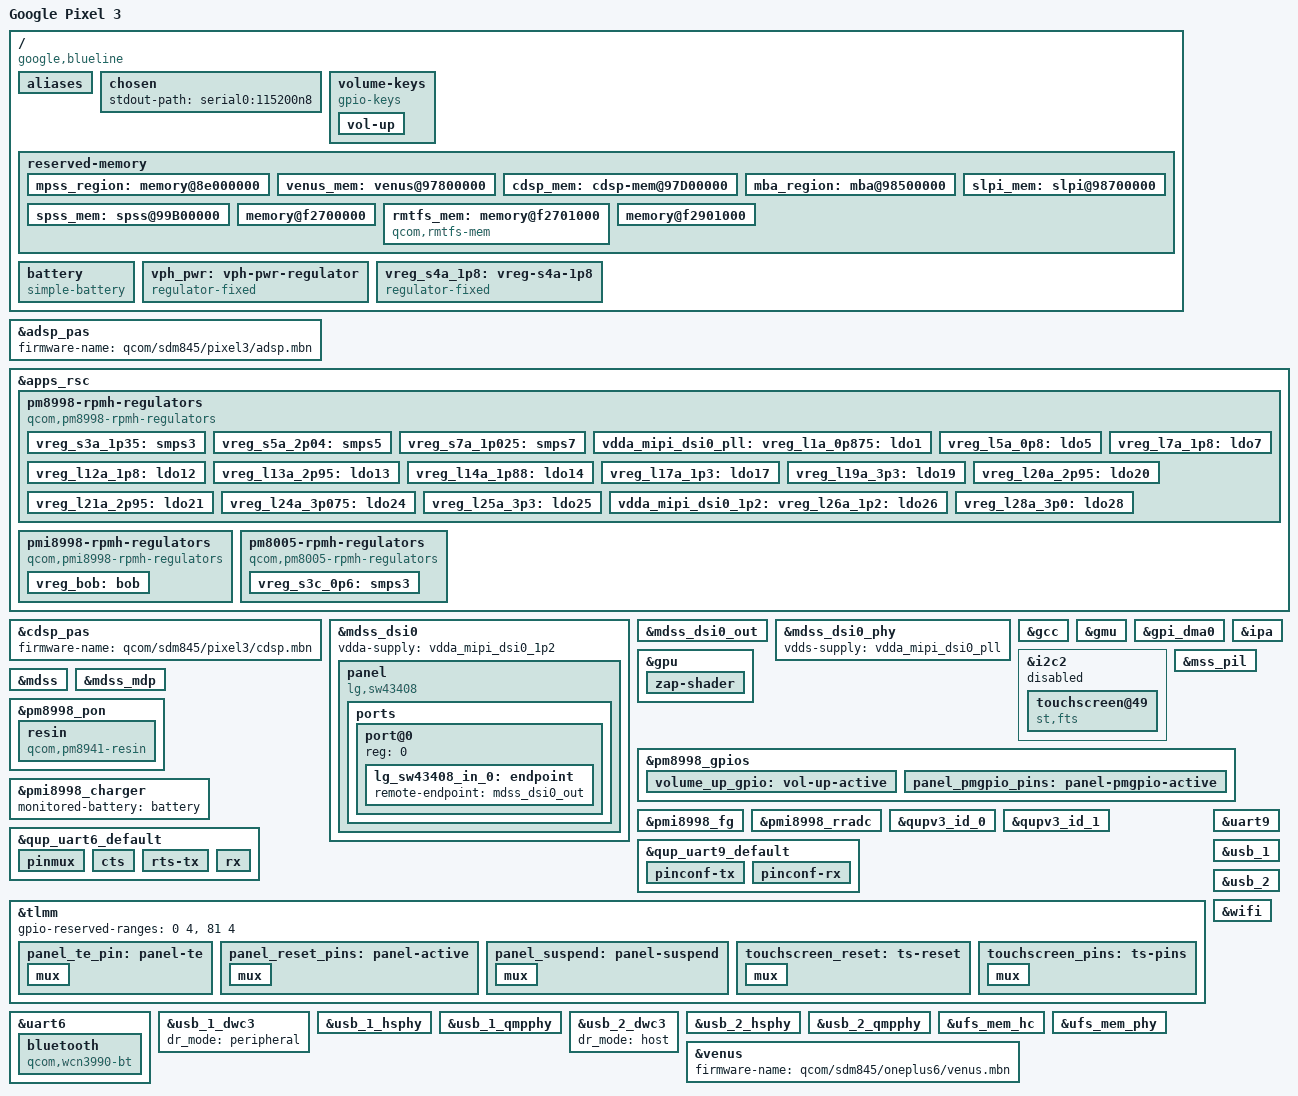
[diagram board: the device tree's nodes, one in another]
// SPDX-License-Identifier: GPL-2.0

/dts-v1/;

#include <dt-bindings/dma/qcom-gpi.h>
#include <dt-bindings/input/linux-event-codes.h>
#include <dt-bindings/interrupt-controller/irq.h>
#include <dt-bindings/regulator/qcom,rpmh-regulator.h>

#include "sdm845.dtsi"
#include "pm8998.dtsi"
#include "pmi8998.dtsi"

/delete-node/ &mpss_region;
/delete-node/ &venus_mem;
/delete-node/ &cdsp_mem;
/delete-node/ &mba_region;
/delete-node/ &slpi_mem;
/delete-node/ &spss_mem;
/delete-node/ &rmtfs_mem;

/ {
	model = "Google Pixel 3";
	compatible = "google,blueline", "qcom,sdm845";
	qcom,board-id = <0x00021505 0>;
	qcom,msm-id = <321 0x20001>;

	aliases {
		serial0 = &uart9;
		serial1 = &uart6;
	};

	chosen {
		stdout-path = "serial0:115200n8";
	};

	volume-keys {
		compatible = "gpio-keys";
		label = "Volume keys";
		autorepeat;

		pinctrl-names = "default";
		pinctrl-0 = <&volume_up_gpio>;

		vol-up {
			label = "Volume Up";
			linux,code = <KEY_VOLUMEUP>;
			gpios = <&pm8998_gpios 6 GPIO_ACTIVE_LOW>;
			debounce-interval = <15>;
		};
	};

	reserved-memory {
		#address-cells = <2>;
		#size-cells = <2>;
		ranges;

		mpss_region: memory@8e000000 {
			reg = <0 0x8e000000 0 0x9800000>;
			no-map;
		};

		venus_mem: venus@97800000 {
			reg = <0 0x97800000 0 0x500000>;
			no-map;
		};

		cdsp_mem: cdsp-mem@97D00000 {
			reg = <0 0x97D00000 0 0x800000>;
			no-map;
		};

		mba_region: mba@98500000 {
			reg = <0 0x98500000 0 0x200000>;
			no-map;
		};

		slpi_mem: slpi@98700000 {
			reg = <0 0x98700000 0 0x1400000>;
			no-map;
		};

		spss_mem: spss@99B00000 {
			reg = <0 0x99B00000 0 0x100000>;
			no-map;
		};

		/* rmtfs lower guard */
		memory@f2700000 {
			reg = <0 0xf2700000 0 0x1000>;
			no-map;
		};

		rmtfs_mem: memory@f2701000 {
			compatible = "qcom,rmtfs-mem";
			reg = <0 0xf2701000 0 0x200000>;
			no-map;

			qcom,client-id = <1>;
			qcom,vmid = <15>;
		};

		/* rmtfs upper guard */
		memory@f2901000 {
			reg = <0 0xf2901000 0 0x1000>;
			no-map;
		};
	};

	battery: battery {
		compatible = "simple-battery";

		charge-full-design-microamp-hours = <2970000>;
		voltage-min-design-microvolt = <3600000>;
		voltage-max-design-microvolt = <4400000>;
	};


	vph_pwr: vph-pwr-regulator {
		compatible = "regulator-fixed";
		regulator-name = "vph_pwr";
		regulator-min-microvolt = <3700000>;
		regulator-max-microvolt = <3700000>;
	};

	vreg_s4a_1p8: vreg-s4a-1p8 {
		compatible = "regulator-fixed";
		regulator-name = "vreg_s4a_1p8";

		regulator-min-microvolt = <1800000>;
		regulator-max-microvolt = <1800000>;
		regulator-always-on;
		regulator-boot-on;

		vin-supply = <&vph_pwr>;
	};
};

&adsp_pas {
	status = "okay";

	firmware-name = "qcom/sdm845/pixel3/adsp.mbn";
};

&apps_rsc {
	pm8998-rpmh-regulators {
		compatible = "qcom,pm8998-rpmh-regulators";
		qcom,pmic-id = "a";
		vdd-s1-supply = <&vph_pwr>;
		vdd-s2-supply = <&vph_pwr>;
		vdd-s3-supply = <&vph_pwr>;
		vdd-s4-supply = <&vph_pwr>;
		vdd-s5-supply = <&vph_pwr>;
		vdd-s6-supply = <&vph_pwr>;
		vdd-s7-supply = <&vph_pwr>;
		vdd-s8-supply = <&vph_pwr>;
		vdd-s9-supply = <&vph_pwr>;
		vdd-s10-supply = <&vph_pwr>;
		vdd-s11-supply = <&vph_pwr>;
		vdd-s12-supply = <&vph_pwr>;
		vdd-s13-supply = <&vph_pwr>;
		vdd-l1-l27-supply = <&vreg_s7a_1p025>;
		vdd-l2-l8-l17-supply = <&vreg_s3a_1p35>;
		vdd-l3-l11-supply = <&vreg_s7a_1p025>;
		vdd-l4-l5-supply = <&vreg_s7a_1p025>;
		vdd-l6-supply = <&vph_pwr>;
		vdd-l7-l12-l14-l15-supply = <&vreg_s5a_2p04>;
		vdd-l9-supply = <&vreg_bob>;
		vdd-l10-l23-l25-supply = <&vreg_bob>;
		vdd-l13-l19-l21-supply = <&vreg_bob>;
		vdd-l16-l28-supply = <&vreg_bob>;
		vdd-l18-l22-supply = <&vreg_bob>;
		vdd-l20-l24-supply = <&vreg_bob>;
		vdd-l26-supply = <&vreg_s3a_1p35>;
		vin-lvs-1-2-supply = <&vreg_s4a_1p8>;

		vreg_s3a_1p35: smps3 {
			regulator-min-microvolt = <1352000>;
			regulator-max-microvolt = <1352000>;
		};

		vreg_s5a_2p04: smps5 {
			regulator-min-microvolt = <1904000>;
			regulator-max-microvolt = <2040000>;
		};

		vreg_s7a_1p025: smps7 {
			regulator-min-microvolt = <900000>;
			regulator-max-microvolt = <1028000>;
		};

		vdda_mipi_dsi0_pll:
		vreg_l1a_0p875: ldo1 {
			regulator-min-microvolt = <880000>;
			regulator-max-microvolt = <880000>;
			regulator-initial-mode = <RPMH_REGULATOR_MODE_HPM>;
			regulator-boot-on;
		};

		vreg_l5a_0p8: ldo5 {
			regulator-min-microvolt = <800000>;
			regulator-max-microvolt = <800000>;
			regulator-initial-mode = <RPMH_REGULATOR_MODE_HPM>;
		};

		vreg_l12a_1p8: ldo12 {
			regulator-min-microvolt = <1800000>;
			regulator-max-microvolt = <1800000>;
			regulator-initial-mode = <RPMH_REGULATOR_MODE_HPM>;
		};

		vreg_l7a_1p8: ldo7 {
			regulator-min-microvolt = <1800000>;
			regulator-max-microvolt = <1800000>;
			regulator-initial-mode = <RPMH_REGULATOR_MODE_HPM>;
		};

		vreg_l13a_2p95: ldo13 {
			regulator-min-microvolt = <1800000>;
			regulator-max-microvolt = <2960000>;
			regulator-initial-mode = <RPMH_REGULATOR_MODE_HPM>;
		};

		vreg_l14a_1p88: ldo14 {
			regulator-min-microvolt = <1800000>;
			regulator-max-microvolt = <1800000>;
			regulator-initial-mode = <RPMH_REGULATOR_MODE_HPM>;
			regulator-boot-on;
			/*
			 * We can't properly bring the panel back if it gets turned off
			 * so keep it's regulators always on for now.
			 */
			regulator-always-on;
		};

		vreg_l17a_1p3: ldo17 {
			regulator-min-microvolt = <1304000>;
			regulator-max-microvolt = <1304000>;
			regulator-initial-mode = <RPMH_REGULATOR_MODE_HPM>;
		};

		vreg_l19a_3p3: ldo19 {
			regulator-min-microvolt = <3300000>;
			regulator-max-microvolt = <3312000>;
			qcom,init-voltage = <3300000>;
			qcom,initial-mode = <RPMH_REGULATOR_MODE_HPM>;
			/*
			 * The touchscreen needs this to be 3.3v, which is apparently
			 * quite close to the hardware limit for this LDO (3.312v)
			 * It must be kept in high power mode to prevent TS brownouts
			 */
			regulator-allowed-modes = <RPMH_REGULATOR_MODE_HPM>;
		};

		vreg_l20a_2p95: ldo20 {
			regulator-min-microvolt = <2960000>;
			regulator-max-microvolt = <2968000>;
			regulator-initial-mode = <RPMH_REGULATOR_MODE_HPM>;
		};

		vreg_l21a_2p95: ldo21 {
			regulator-min-microvolt = <2960000>;
			regulator-max-microvolt = <2968000>;
			regulator-initial-mode = <RPMH_REGULATOR_MODE_HPM>;
		};

		vreg_l24a_3p075: ldo24 {
			regulator-min-microvolt = <3088000>;
			regulator-max-microvolt = <3088000>;
			regulator-initial-mode = <RPMH_REGULATOR_MODE_HPM>;
		};

		vreg_l25a_3p3: ldo25 {
			regulator-min-microvolt = <3300000>;
			regulator-max-microvolt = <3312000>;
			regulator-initial-mode = <RPMH_REGULATOR_MODE_HPM>;
		};

		vdda_mipi_dsi0_1p2:
		vreg_l26a_1p2: ldo26 {
			regulator-min-microvolt = <1200000>;
			regulator-max-microvolt = <1200000>;
			regulator-initial-mode = <RPMH_REGULATOR_MODE_HPM>;
			regulator-boot-on;
		};

		vreg_l28a_3p0: ldo28 {
			regulator-min-microvolt = <2856000>;
			regulator-max-microvolt = <3008000>;
			regulator-initial-mode = <RPMH_REGULATOR_MODE_HPM>;
			regulator-boot-on;
			/*
			 * We can't properly bring the panel back if it gets turned off
			 * so keep it's regulators always on for now.
			 */
			regulator-always-on;
		};
	};

	pmi8998-rpmh-regulators {
		compatible = "qcom,pmi8998-rpmh-regulators";
		qcom,pmic-id = "b";

		vdd-bob-supply = <&vph_pwr>;

		vreg_bob: bob {
			regulator-min-microvolt = <3312000>;
			regulator-max-microvolt = <3600000>;
			regulator-initial-mode = <RPMH_REGULATOR_MODE_AUTO>;
			regulator-allow-bypass;
		};
	};

	pm8005-rpmh-regulators {
		compatible = "qcom,pm8005-rpmh-regulators";
		qcom,pmic-id = "c";

		vdd-s1-supply = <&vph_pwr>;
		vdd-s2-supply = <&vph_pwr>;
		vdd-s3-supply = <&vph_pwr>;
		vdd-s4-supply = <&vph_pwr>;

		vreg_s3c_0p6: smps3 {
			regulator-min-microvolt = <600000>;
			regulator-max-microvolt = <600000>;
		};
	};
};

&cdsp_pas {
	status = "okay";
	firmware-name = "qcom/sdm845/pixel3/cdsp.mbn";
};

&mdss_dsi0 {
	status = "okay";
	vdda-supply = <&vdda_mipi_dsi0_1p2>;

	panel {
		compatible = "lg,sw43408";
		reg = <0>;

		vddi-supply = <&vreg_l14a_1p88>;
		vpnl-supply = <&vreg_l28a_3p0>;

		reset-gpios = <&tlmm 6 GPIO_ACTIVE_LOW>;

		pinctrl-names = "default";
		pinctrl-0 = <&panel_reset_pins &panel_te_pin &panel_pmgpio_pins>;

		ports {
			#address-cells = <1>;
			#size-cells = <0>;

			port@0 {
				reg = <0>;
				lg_sw43408_in_0: endpoint {
					remote-endpoint = <&mdss_dsi0_out>;
				};
			};
		};
	};
};

&mdss_dsi0_out {
	remote-endpoint = <&lg_sw43408_in_0>;
	data-lanes = <0 1 2 3>;
};

&mdss_dsi0_phy {
	status = "okay";
	vdds-supply = <&vdda_mipi_dsi0_pll>;
};

&gcc {
	protected-clocks = <GCC_QSPI_CORE_CLK>,
			   <GCC_QSPI_CORE_CLK_SRC>,
			   <GCC_QSPI_CNOC_PERIPH_AHB_CLK>;
};

&gmu {
	status = "okay";
};

&gpi_dma0 {
	status = "okay";
};

&gpu {
	status = "okay";

	zap-shader {
		memory-region = <&gpu_mem>;
		firmware-name = "qcom/sdm845/pixel3/a630_zap.mbn";
	};
};

&i2c2 {
	status = "disabled";
	#dma-cells = <3>;

	dmas =  <&gpi_dma0 0 2 QCOM_GPI_I2C>,
		<&gpi_dma0 1 2 QCOM_GPI_I2C>;
	dma-names = "tx", "rx";

	touchscreen@49 {
		compatible = "st,fts";
		reg = <0x49>;
		pinctrl-names = "default";
		pinctrl-0 = <&touchscreen_pins &touchscreen_reset>;
		interrupt-parent = <&tlmm>;
		interrupts = <125 IRQ_TYPE_LEVEL_LOW>;
		avdd-supply = <&vreg_l14a_1p88>;
		vdd-supply = <&vreg_l19a_3p3>;
		// touchscreen-size-x = <1080>;
		// touchscreen-size-y = <2160>;

		st,irq-gpio = <&tlmm 125 0>;
		st,reset-gpio = <&tlmm 99 0>;
		st,switch_gpio = <&tlmm 136 0>;
		st,max-coords = <1079 2159>;
		st,regulator_dvdd = "vdd";
		st,regulator_avdd = "avdd";
	};
};

&ipa {
	status = "okay";

	memory-region = <&ipa_fw_mem>;
	firmware-name = "qcom/sdm845/pixel3/ipa_fws.mbn";
};

&mss_pil {
	status = "okay";
	firmware-name = "qcom/sdm845/pixel3/mba.mbn", "qcom/sdm845/pixel3/modem.mbn";
};

&mdss {
	status = "okay";
};

&mdss_mdp {
	status = "okay";
};

&pm8998_gpios {
	volume_up_gpio: vol-up-active {
		pins = "gpio6";
		function = "normal";
		input-enable;
		bias-pull-up;
		qcom,drive-strength = <0>;
	};

	panel_pmgpio_pins: panel-pmgpio-active {
		pins = "gpio2", "gpio5";
		function = "normal";
		input-enable;
		bias-disable;
		power-source = <0>;
	};
};

&pm8998_pon {
	resin {
		compatible = "qcom,pm8941-resin";
		interrupts = <0x0 0x8 1 IRQ_TYPE_EDGE_BOTH>;
		debounce = <15625>;
		bias-pull-up;
		linux,code = <KEY_VOLUMEDOWN>;
	};
};

&pmi8998_charger {
	status = "okay";
	monitored-battery = <&battery>;
};

&pmi8998_fg {
	status = "okay";
	monitored-battery = <&battery>;
	power-supplies = <&pmi8998_charger>;
};

&pmi8998_rradc {
	status = "okay";
};

&qupv3_id_0 {
	status = "okay";
};

&qupv3_id_1 {
	status = "okay";
};

&qup_uart6_default {
	pinmux {
		pins = "gpio45", "gpio46", "gpio47", "gpio48";
		function = "qup6";
	};

	cts {
		pins = "gpio45";
		bias-disable;
	};

	rts-tx {
		pins = "gpio46", "gpio47";
		drive-strength = <2>;
		bias-disable;
	};

	rx {
		pins = "gpio48";
		bias-pull-up;
	};
};

&qup_uart9_default {
	pinconf-tx {
		pins = "gpio4";
		drive-strength = <2>;
		bias-disable;
	};

	pinconf-rx {
		pins = "gpio5";
		drive-strength = <2>;
		bias-pull-up;
	};
};

&tlmm {
	gpio-reserved-ranges = <0 4>, <81 4>;

	panel_te_pin: panel-te {
		mux {
			pins = "gpio12";
			function = "mdp_vsync";
			drive-strength = <2>;
			bias-disable;
			input-enable;
		};
	};

	panel_reset_pins: panel-active {
		mux {
			pins = "gpio6", "gpio52";
			function = "gpio";
			drive-strength = <8>;
			bias-disable = <0>;
		};
	};

	panel_suspend: panel-suspend {
		mux {
			pins = "gpio6", "gpio52";
			function = "gpio";
			drive-strength = <2>;
			bias-pull-down;
		};
	};

	touchscreen_reset: ts-reset {
		mux {
			pins = "gpio99";
			function = "gpio";
			drive-strength = <8>;
			bias-pull-up;
			//output-high;
		};
	};

	touchscreen_pins: ts-pins {
		mux {
			pins = "gpio125";
			function = "gpio";
			drive-strength = <2>;
			bias-disable;
		};
	};
};

&uart6 {
	status = "okay";

	bluetooth {
		compatible = "qcom,wcn3990-bt";

		vddio-supply = <&vreg_s4a_1p8>;
		vddxo-supply = <&vreg_l7a_1p8>;
		vddrf-supply = <&vreg_l17a_1p3>;
		vddch0-supply = <&vreg_l25a_3p3>;
		max-speed = <3200000>;
	};
};

&uart9 {
	status = "okay";
};

&usb_1 {
	status = "okay";
};

&usb_1_dwc3 {
	dr_mode = "peripheral";
};

&usb_1_hsphy {
	status = "okay";

	vdd-supply = <&vreg_l1a_0p875>;
	vdda-pll-supply = <&vreg_l12a_1p8>;
	vdda-phy-dpdm-supply = <&vreg_l24a_3p075>;

	qcom,imp-res-offset-value = <8>;
	qcom,hstx-trim-value = <QUSB2_V2_HSTX_TRIM_21_6_MA>;
	qcom,preemphasis-level = <QUSB2_V2_PREEMPHASIS_5_PERCENT>;
	qcom,preemphasis-width = <QUSB2_V2_PREEMPHASIS_WIDTH_HALF_BIT>;
};

&usb_1_qmpphy {
	status = "okay";

	vdda-phy-supply = <&vreg_l26a_1p2>;
	vdda-pll-supply = <&vreg_l1a_0p875>;
};

&usb_2 {
	status = "okay";
};

&usb_2_dwc3 {
	dr_mode = "host";
};

&usb_2_hsphy {
	status = "okay";

	vdd-supply = <&vreg_l1a_0p875>;
	vdda-pll-supply = <&vreg_l12a_1p8>;
	vdda-phy-dpdm-supply = <&vreg_l24a_3p075>;

	qcom,imp-res-offset-value = <8>;
	qcom,hstx-trim-value = <QUSB2_V2_HSTX_TRIM_22_8_MA>;
};

&usb_2_qmpphy {
	status = "okay";

	vdda-phy-supply = <&vreg_l26a_1p2>;
	vdda-pll-supply = <&vreg_l1a_0p875>;
};

&ufs_mem_hc {
	status = "okay";

	reset-gpios = <&tlmm 150 GPIO_ACTIVE_LOW>;

	vcc-supply = <&vreg_l20a_2p95>;
	vcc-max-microamp = <800000>;
};

&ufs_mem_phy {
	status = "okay";

	vdda-phy-supply = <&vreg_l1a_0p875>;
	vdda-pll-supply = <&vreg_l26a_1p2>;
};

&venus {
	status = "okay";
	firmware-name = "qcom/sdm845/oneplus6/venus.mbn";
};

&wifi {
	status = "okay";

	vdd-0.8-cx-mx-supply = <&vreg_l5a_0p8>;
	vdd-1.8-xo-supply = <&vreg_l7a_1p8>;
	vdd-1.3-rfa-supply = <&vreg_l17a_1p3>;
	vdd-3.3-ch0-supply = <&vreg_l25a_3p3>;

	qcom,snoc-host-cap-8bit-quirk;
	qcom,ath10k-calibration-variant = "google_blueline";
};
